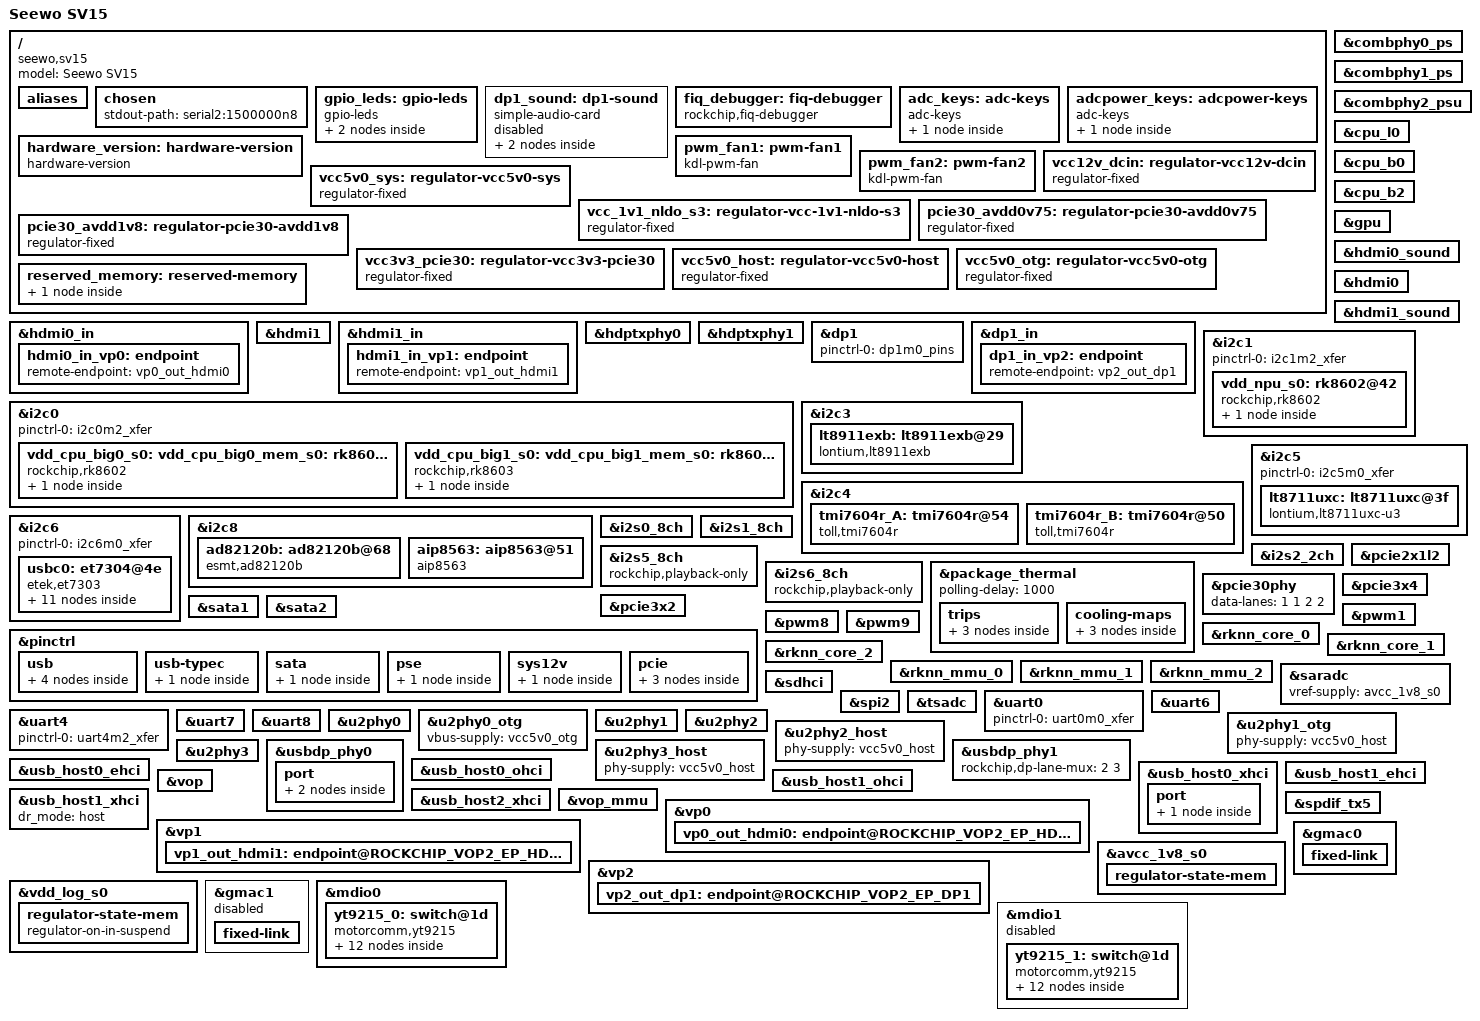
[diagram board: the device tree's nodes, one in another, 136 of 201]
// SPDX-License-Identifier: (GPL-2.0+ OR MIT)
/*
 * Copyright (c) 2026 ColtPlus
 */

/dts-v1/;

#include <dt-bindings/gpio/gpio.h>
#include <dt-bindings/leds/common.h>
#include <dt-bindings/pwm/pwm.h>
#include <dt-bindings/pinctrl/rockchip.h>
#include <dt-bindings/input/linux-event-codes.h>
#include <dt-bindings/soc/rockchip,vop2.h>
#include <dt-bindings/usb/pd.h>
#include "rk3588.dtsi"
#include "rk3588-rk806-single.dtsi"

/ {
	model = "Seewo SV15";
	compatible = "seewo,sv15", "rockchip,rk3588";

	aliases {
		mmc0 = &sdmmc;
		mmc1 = &sdhci;
		mmc2 = &sdio;
	};

	chosen {
		stdout-path = "serial2:1500000n8";
	};

	gpio_leds: gpio-leds {
		compatible = "gpio-leds";
		pinctrl-names = "default";

		user-led {
			gpios = <&gpio4 RK_PD0 GPIO_ACTIVE_HIGH>;
			linux,default-trigger = "boot";
			default-state = "on";
		};

		sys-led {
			gpios = <&gpio4 RK_PD1 GPIO_ACTIVE_HIGH>;
			linux,default-trigger = "alarm";
		};
	};

	dp1_sound: dp1-sound {
		compatible = "simple-audio-card";
		simple-audio-card,name = "rockchip,dp1";
		simple-audio-card,mclk-fs = <512>;
		status = "disabled";

		simple-audio-card, {
			sound-dai = <&spdif_tx5>;
		};

		simple-audio-card,codec {
			sound-dai = <&dp1>;
		};
	};

	fiq_debugger: fiq-debugger {
		compatible = "rockchip,fiq-debugger";
		rockchip,serial-id = <2>;
		rockchip,wake-irq = <0>;
		rockchip,irq-mode-enable = <1>;
		rockchip,baudrate = <1500000>;
		interrupts = <GIC_SPI 423 IRQ_TYPE_LEVEL_LOW>;
		pinctrl-names = "default";
		pinctrl-0 = <&uart2m0_xfer>;
		status = "okay";
	};

	adc_keys: adc-keys {
		compatible = "adc-keys";
		io-channels = <&saradc 1>;
		io-channel-names = "buttons";
		keyup-threshold-microvolt = <1800000>;
		poll-interval = <100>;

		vol-up-key {
			label = "volume up";
			linux,code = <KEY_VOLUMEUP>;
			press-threshold-microvolt = <1750>;
		};
	};

	adcpower_keys: adcpower-keys {
		compatible = "adc-keys";
		io-channels = <&saradc 3>;
		io-channel-names = "buttons";
		keyup-threshold-microvolt = <1800000>;
		poll-interval = <100>;

		adc-power-key {
			label = "power key";
			linux,code = <KEY_POWER>;
			press-threshold-microvolt = <1750>;
			wakeup-source;
		};
	};

	hardware_version: hardware-version {
		compatible = "hardware-version";
		io-channels = <&saradc 5 &saradc 7>;
		io-channel-names = "ADC5", "ADC7";
		keyup-threshold-microvolt = <1800000>;
		poll-interval = <100>;
	};


	pwm_fan1: pwm-fan1 {
		compatible = "kdl-pwm-fan";
		pwm-names = "fan1";
		pwms = <&pwm8 0 40000 0>;
		pwm-frequency = <25000>;
		rd-gpios = <&gpio3 RK_PA0 GPIO_ACTIVE_HIGH>;
		pwm-polarity-inversed;
	};

	pwm_fan2: pwm-fan2 {
		compatible = "kdl-pwm-fan";
		pwm-names = "fan2";
		pwms = <&pwm9 0 40000 0>;
		pwm-frequency = <25000>;
		rd-gpios = <&gpio3 RK_PA1 GPIO_ACTIVE_HIGH>;
		pwm-polarity-inversed;
	};

	vcc12v_dcin: regulator-vcc12v-dcin {
		compatible = "regulator-fixed";
		regulator-name = "vcc12v_dcin";
		regulator-always-on;
		regulator-boot-on;
		regulator-min-microvolt = <12000000>;
		regulator-max-microvolt = <12000000>;
	};

	vcc5v0_sys: regulator-vcc5v0-sys {
		compatible = "regulator-fixed";
		regulator-name = "vcc5v0_sys";
		regulator-always-on;
		regulator-boot-on;
		regulator-min-microvolt = <5000000>;
		regulator-max-microvolt = <5000000>;
		vin-supply = <&vcc12v_dcin>;
	};

	vcc_1v1_nldo_s3: regulator-vcc-1v1-nldo-s3 {
		compatible = "regulator-fixed";
		regulator-name = "vcc_1v1_nldo_s3";
		regulator-always-on;
		regulator-boot-on;
		regulator-min-microvolt = <1100000>;
		regulator-max-microvolt = <1100000>;
		vin-supply = <&vcc5v0_sys>;
	};

	pcie30_avdd0v75: regulator-pcie30-avdd0v75 {
		compatible = "regulator-fixed";
		regulator-name = "pcie30_avdd0v75";
		regulator-boot-on;
		regulator-always-on;
		regulator-min-microvolt = <750000>;
		regulator-max-microvolt = <750000>;
		vin-supply = <&vdd_0v75_s0>;
	};

	pcie30_avdd1v8: regulator-pcie30-avdd1v8 {
		compatible = "regulator-fixed";
		regulator-name = "pcie30_avdd1v8";
		regulator-boot-on;
		regulator-always-on;
		regulator-min-microvolt = <1800000>;
		regulator-max-microvolt = <1800000>;
		vin-supply = <&avcc_1v8_s0>;
	};

	vcc3v3_pcie30: regulator-vcc3v3-pcie30 {
		compatible = "regulator-fixed";
		enable-active-high;
		gpios = <&gpio1 RK_PB6 GPIO_ACTIVE_HIGH>;
		regulator-name = "vcc3v3_pcie30";
		regulator-min-microvolt = <3300000>;
		regulator-max-microvolt = <3300000>;
		startup-delay-us = <7500>;
		vin-supply = <&vcc12v_dcin>;
	};

	vcc5v0_host: regulator-vcc5v0-host {
		compatible = "regulator-fixed";
		regulator-name = "vcc5v0_host";
		regulator-boot-on;
		regulator-always-on;
		regulator-min-microvolt = <5000000>;
		regulator-max-microvolt = <5000000>;
		vin-supply = <&vcc5v0_sys>;
		enable-active-high;
		gpio = <&gpio4 RK_PB0 GPIO_ACTIVE_HIGH>;
		pinctrl-names = "default";
		pinctrl-0 = <&vcc5v0_host_en>;
	};

	vcc5v0_otg: regulator-vcc5v0-otg {
		compatible = "regulator-fixed";
		regulator-name = "vcc5v0_otg";
		regulator-boot-on;
		regulator-always-on;
		regulator-min-microvolt = <5000000>;
		regulator-max-microvolt = <5000000>;
		enable-active-high;
		gpio = <&gpio4 RK_PA3 GPIO_ACTIVE_HIGH>;
		vin-supply = <&vcc5v0_sys>;
		pinctrl-names = "default";
		pinctrl-0 = <&vcc5v0_otg_en>;
	};

	reserved_memory: reserved-memory {
		#address-cells = <2>;
		#size-cells = <2>;
		ranges;

		cma: linux,cma@10000000 {
			compatible = "shared-dma-pool";
			reusable;
			reg = <0x0 (256 * 0x100000) 0x0 (256 * 0x100000)>;
			linux,cma-default;
		};
	};
};

&combphy0_ps {
	status = "okay";
};

&combphy1_ps {
	status = "okay";
};

&combphy2_psu {
	status = "okay";
};

&cpu_l0 {
	cpu-supply = <&vdd_cpu_lit_s0>;
	mem-supply = <&vdd_cpu_lit_mem_s0>;
};

&cpu_b0 {
	cpu-supply = <&vdd_cpu_big0_s0>;
	mem-supply = <&vdd_cpu_big0_mem_s0>;
};

&cpu_b2 {
	cpu-supply = <&vdd_cpu_big1_s0>;
	mem-supply = <&vdd_cpu_big1_mem_s0>;
};

&gpu {
	upthreshold = <30>;
	downdifferential = <10>;
	mali-supply = <&vdd_gpu_s0>;
	mem-supply = <&vdd_gpu_mem_s0>;
	status = "okay";
};

&hdmi0_sound {
	status = "okay";
};

&hdmi0 {
	pinctrl-names = "default";
	pinctrl-0 = <&hdmim0_tx0_hpd &hdmim0_tx0_scl &hdmim0_tx0_sda>;
	frl-enable-gpios = <&gpio4 RK_PB5 GPIO_ACTIVE_LOW>;
	status = "okay";
};

&hdmi0_in {
	hdmi0_in_vp0: endpoint {
		remote-endpoint = <&vp0_out_hdmi0>;
	};
};

&hdmi1_sound {
	status = "okay";
};

&hdmi1 {
	pinctrl-names = "default";
	pinctrl-0 = <&hdmim0_tx1_hpd &hdmim1_tx1_scl &hdmim1_tx1_sda>;
	frl-enable-gpios = <&gpio4 RK_PB6 GPIO_ACTIVE_LOW>;
	status = "okay";
};

&hdmi1_in {
	hdmi1_in_vp1: endpoint {
		remote-endpoint = <&vp1_out_hdmi1>;
	};
};

&hdptxphy0 {
	status = "okay";
};

&hdptxphy1 {
	status = "okay";
};

&dp1 {
	status = "okay";
	pinctrl-0 = <&dp1m0_pins>;
	pinctrl-names = "default";
};

&dp1_in {
	dp1_in_vp2: endpoint {
		remote-endpoint = <&vp2_out_dp1>;
	};
};

&i2c0 {
	status = "okay";
	pinctrl-names = "default";
	pinctrl-0 = <&i2c0m2_xfer>;

	vdd_cpu_big0_s0: vdd_cpu_big0_mem_s0: rk8602@42 {
		compatible = "rockchip,rk8602";
		reg = <0x42>;
		vin-supply = <&vcc5v0_sys>;
		fcs,suspend-voltage-selector = <1>;
		regulator-name = "vdd_cpu_big0_s0";
		regulator-min-microvolt = <550000>;
		regulator-max-microvolt = <1050000>;
		regulator-ramp-delay = <2300>;
		regulator-boot-on;
		regulator-always-on;

		regulator-state-mem {
			regulator-off-in-suspend;
		};
	};

	vdd_cpu_big1_s0: vdd_cpu_big1_mem_s0: rk8603@43 {
		compatible = "rockchip,rk8603", "rockchip,rk8602";
		reg = <0x43>;
		vin-supply = <&vcc5v0_sys>;
		fcs,suspend-voltage-selector = <1>;
		regulator-name = "vdd_cpu_big1_s0";
		regulator-min-microvolt = <550000>;
		regulator-max-microvolt = <1050000>;
		regulator-ramp-delay = <2300>;
		regulator-boot-on;
		regulator-always-on;

		regulator-state-mem {
			regulator-off-in-suspend;
		};
	};
};

&i2c1 {
	status = "okay";
	pinctrl-names = "default";
	pinctrl-0 = <&i2c1m2_xfer>;

	vdd_npu_s0: rk8602@42 {
		compatible = "rockchip,rk8602";
		reg = <0x42>;
		vin-supply = <&vcc5v0_sys>;
		fcs,suspend-voltage-selector = <1>;
		regulator-name = "vdd_npu_s0";
		regulator-min-microvolt = <550000>;
		regulator-max-microvolt = <950000>;
		regulator-ramp-delay = <2300>;
		regulator-boot-on;
		regulator-always-on;

		regulator-state-mem {
			regulator-off-in-suspend;
		};
	};
};

&i2c3 {
	pinctrl-names = "default";
	pinctrl-0 = <&i2c3m0_xfer>;
	clock-frequency = <100000>;
	status = "okay";

	lt8911exb: lt8911exb@29 {
		compatible = "lontium,lt8911exb";
		reg = <0x29>;
		/*bl-on-gpios = <0x12c 0x0f 0x00>;
		panel-pwren-gpios = <0x12d 0x14 0x00>;
		bl-pwren-gpios = <0x12d 0x15 0x00>;
		rst-gpios = <0xf1 0x14 0x00>;*/
		bl-on-gpios = <&gpio0 RK_PB7 GPIO_ACTIVE_HIGH>;
		panel-pwren-gpios = <&gpio2 RK_PC4 GPIO_ACTIVE_HIGH>;
		bl-pwren-gpios = <&gpio2 RK_PC5 GPIO_ACTIVE_HIGH>;
		reset-gpios = <&gpio1 RK_PC4 GPIO_ACTIVE_HIGH>;
		status = "okay";
	};
};

&i2c4 {
	status = "okay";
	
	tmi7604r_A: tmi7604r@54 {
		status = "okay";
		compatible = "toll,tmi7604r";
		kdl,poe-module-name = "tmi7604r_A";
		reg = <0x54>;
		/*pse-intb-gpios = <0xf1 0x1e 0x00>;*/
		pse-intb-gpios = <&gpio1 RK_PD6 GPIO_ACTIVE_HIGH>;
		my-conf = <0x01>;
	};

	tmi7604r_B: tmi7604r@50 {
		status = "okay";
		compatible = "toll,tmi7604r";
		kdl,poe-module-name = "tmi7604r_B";
		reg = <0x50>;
		/*pse-intb-gpios = <0xf1 0x13 0x00>;*/
		pse-intb-gpios = <&gpio1 RK_PC3 GPIO_ACTIVE_HIGH>;
		my-conf = <0x02>;
	};
};

&i2c5 {
	#address-cells = <1>;
	#size-cells = <0>;
	pinctrl-names = "default";
	pinctrl-0 = <&i2c5m0_xfer>;
	status = "okay";

	/*lt6911c_A: lt6911c_A@2b {
		status = "okay";
		compatible = "lontium,lt6911c";
		reg = <0x2b>;
		clocks = <&cru CLK_MIPI_CAMARAOUT_M2>;
		clock-names = "xvclk";
		reset-gpios = <&gpio4 RK_PC1 GPIO_ACTIVE_HIGH>;
		res-change-gpios = <&gpio3 RK_PC3 GPIO_ACTIVE_HIGH>;
		plugin-det-gpios = <&gpio3 RK_PD1 GPIO_ACTIVE_HIGH>;
		rockchip,camera-module-index = <0>;
		rockchip,camera-module-facing = "back";
		rockchip,camera-module-name = "lt6911c_A";
		rockchip,camera-module-lens-name = "NC";
		cvte,hdmi-port-name = "HDMIIN1";

		port {

			endpoint {
				remote-endpoint = <&csi2_dcphy1_ports_port0_endpoint1>;
				data-lanes = <1 2 3 4>;
			};
		};
	};*/

	lt8711uxc: lt8711uxc@3f {
		compatible = "lontium,lt8711uxc-u3";
		reg = <0x3f>;
		plugin-det-gpios = <&gpio3 RK_PD5 GPIO_ACTIVE_HIGH>;
		reset-gpios = <&gpio3 RK_PB2 GPIO_ACTIVE_HIGH>;
		status = "okay";
	};
};

&i2c6 {
	pinctrl-names = "default";
	pinctrl-0 = <&i2c6m0_xfer>;
	status = "okay";

	usbc0: et7304@4e {
		compatible = "etek,et7303";
		reg = <0x4e>;
		interrupt-parent = <&gpio4>;
		interrupts = <RK_PA4 IRQ_TYPE_LEVEL_LOW>;
		pinctrl-names = "default";
		pinctrl-0 = <&usbc0_int>;
		vbus-supply = <&vcc5v0_otg>;
		status = "okay";

		ports {
			#address-cells = <1>;
			#size-cells = <0>;

			port@0 {
				reg = <0>;
				usbc0_role_sw: endpoint {
					remote-endpoint = <&dwc3_0_role_switch>;
				};
			};
		};

		usb_con: connector {
			compatible = "usb-c-connector";
			label = "USB-C";
			data-role = "dual";
			power-role = "dual";
			try-power-role = "sink";
			op-sink-microwatt = <1000000>;
			sink-pdos = <PDO_FIXED(5000, 1000, PDO_FIXED_USB_COMM)>;
			source-pdos = <PDO_FIXED(5000, 3000, PDO_FIXED_USB_COMM)>;

			altmodes {
				#address-cells = <1>;
				#size-cells = <0>;

				altmode@0 {
					reg = <0>;
					svid = <0xff01>;
					vdo = <0xffffffff>;
				};
			};

			ports {
				#address-cells = <1>;
				#size-cells = <0>;

				port@0 {
					reg = <0>;
					usbc0_orien_sw: endpoint {
						remote-endpoint = <&usbdp_phy0_orientation_switch>;
					};
				};

				port@1 {
					reg = <1>;
					dp_altmode_mux: endpoint {
						remote-endpoint = <&usbdp_phy0_dp_altmode_mux>;
					};
				};
			};
		};
	};
};

&i2c8 {
	pinctrl-names = "default";
	pinctrl-0 = <&i2c8m4_xfer>;
	status = "okay";
	clock-frequency = <100000>;

	ad82120b: ad82120b@68 {
		compatible = "esmt,ad82120b";
		reg = <0x68>;
		#sound-dai-cells = <0x00>;
		mute-gpios = <&gpio3 RK_PB1 GPIO_ACTIVE_HIGH>;
		no_mclk;
		status = "okay";
	};

	aip8563: aip8563@51 {
		compatible = "aip8563";
		reg = <0x51>;
		interrupt-parent = <&gpio1>;
		interrupts = <RK_PB5 IRQ_TYPE_LEVEL_LOW>;
		status = "okay";
	};
};

&i2s0_8ch {
	status = "okay";
};

&i2s1_8ch {
	pinctrl-names = "default";
	assigned-clocks = <&cru CLK_I2S1_8CH_RX>;
	assigned-clock-parents = <&cru CLK_I2S1_8CH_TX_SRC>;
	status = "okay";
};

&i2s2_2ch {
	pinctrl-names = "default";
	pinctrl-0 = <&i2s2m1_lrck
		     &i2s2m1_sclk
		     &i2s2m1_sdo>;
	status = "okay";
};

&i2s5_8ch {
	rockchip,playback-only;
	status = "okay";
};

&i2s6_8ch {
	rockchip,playback-only;
	status = "okay";
};

&package_thermal {
	polling-delay = <1000>;

	trips {
		package_fan0: package-fan0 {
			temperature = <50000>;
			hysteresis = <2000>;
			type = "active";
		};

		package_fan1: package-fan1 {
			temperature = <60000>;
			hysteresis = <2000>;
			type = "active";
		};

		package_fan2: package-fan2 {
			temperature = <70000>;
			hysteresis = <2000>;
			type = "active";
		};
	};

	cooling-maps {
		map0 {
			trip = <&package_fan0>;
			cooling-device = <&pwm_fan1 THERMAL_NO_LIMIT 2>;
		};

		map1 {
			trip = <&package_fan1>;
			cooling-device = <&pwm_fan1 3 5>;
		};

		map2 {
			trip = <&package_fan2>;
			cooling-device = <&pwm_fan1 6 THERMAL_NO_LIMIT>;
		};
	};
};

&pcie2x1l2 {
	pinctrl-names = "default";
	pinctrl-0 = <&pcie2_2_rst>;
	reset-gpios = <&gpio1 RK_PB4 GPIO_ACTIVE_HIGH>;
	status = "okay";
};

&pcie30phy {
	data-lanes = <1 1 2 2>;
	status = "okay";
};

&pcie3x4 {
	num-lanes = <2>;
	max-link-speed = <3>;
	pinctrl-names = "default";
	pinctrl-0 = <&pcie3x4_rst>;
	reset-gpios = <&gpio1 RK_PA7 GPIO_ACTIVE_HIGH>;
	vpcie3v3-supply = <&vcc3v3_pcie30>;
	status = "okay";
};

&pcie3x2 {
	num-lanes = <2>;
	max-link-speed = <3>;
	pinctrl-names = "default";
	pinctrl-0 = <&pcie3x2_rst>;
	reset-gpios = <&gpio1 RK_PB7 GPIO_ACTIVE_HIGH>;
	vpcie3v3-supply = <&vcc3v3_pcie30>;
	status = "okay";
};

&sata1 {
	status = "okay";
};

&sata2 {
	status = "okay";
};

&pinctrl {
	usb {
		vcc5v0_host_en: vcc5v0-host-en {
			rockchip,pins = <4 RK_PB0 RK_FUNC_GPIO &pcfg_pull_none>;
		};

		vcc5v0_otg_en: vcc5v0-otg-en {
			rockchip,pins = <4 RK_PA3 RK_FUNC_GPIO &pcfg_pull_none>;
		};

		usb20_pwren: usb20-pwren {
			rockchip,pins = <1 RK_PC2 RK_FUNC_GPIO &pcfg_output_high>;
		};

		usb30_pwren: usb30-pwren {
			rockchip,pins = <1 RK_PC6 RK_FUNC_GPIO &pcfg_output_high>;
		};
	};

	usb-typec {
		usbc0_int: usbc0-int {
			rockchip,pins = <4 RK_PA4 RK_FUNC_GPIO &pcfg_pull_up>;
		};
	};

	sata {
		sata_pwren: sata-pwren {
			rockchip,pins = <1 RK_PD4 RK_FUNC_GPIO &pcfg_pull_none>;
		};
	};

	pse {
		pse_pwren: pse-pwren {
			rockchip,pins = <4 RK_PA0 RK_FUNC_GPIO &pcfg_pull_none>;
		};
	};

	sys12v {
		sys12v_pwren: sys12v-pwren {
			rockchip,pins = <1 RK_PC7 RK_FUNC_GPIO &pcfg_pull_none>;
		};
	};

	pcie {
		pcie2_2_rst: pcie2-2-rst {
			rockchip,pins = <1 RK_PB4 RK_FUNC_GPIO &pcfg_pull_none>;
		};

		pcie3x2_rst: pcie3x2-rst {
			rockchip,pins = <1 RK_PB7 RK_FUNC_GPIO &pcfg_pull_none>;
		};

		pcie3x4_rst: pcie3x4-rst {
			rockchip,pins = <1 RK_PA7 RK_FUNC_GPIO &pcfg_pull_none>;
		};
	};
};

&pwm1 {
	status = "okay";
};

&pwm8 {
	status = "okay";
};

&pwm9 {
	status = "okay";
};

&rknn_core_0 {
	npu-supply = <&vdd_npu_s0>;
	sram-supply = <&vdd_npu_s0>;
	status = "okay";
};

&rknn_core_1 {
	npu-supply = <&vdd_npu_s0>;
	sram-supply = <&vdd_npu_s0>;
	status = "okay";
};

&rknn_core_2 {
	npu-supply = <&vdd_npu_s0>;
	sram-supply = <&vdd_npu_s0>;
	status = "okay";
};

&rknn_mmu_0 {
	status = "okay";
};

&rknn_mmu_1 {
	status = "okay";
};

&rknn_mmu_2 {
	status = "okay";
};

&saradc {
	vref-supply = <&avcc_1v8_s0>;
	status = "okay";
};

&sdhci {
	bus-width = <8>;
	no-sdio;
	no-sd;
	non-removable;
	mmc-hs400-1_8v;
	mmc-hs400-enhanced-strobe;
	status = "okay";
};

&spi2 {
	status = "okay";
};

&tsadc {
	status = "okay";
};

&uart0 {
	pinctrl-0 = <&uart0m0_xfer>;
	status = "okay";
};

&uart4 {
	pinctrl-0 = <&uart4m2_xfer>;
	status = "okay";
};

&uart6 {
	status = "okay";
};

&uart7 {
	status = "okay";
};

&uart8 {
	status = "okay";
};

&u2phy0 {
	status = "okay";
};

&u2phy0_otg {
	vbus-supply = <&vcc5v0_otg>;
	status = "okay";
};

&u2phy1 {
	status = "okay";
};

&u2phy1_otg {
	phy-supply = <&vcc5v0_host>;
	status = "okay";
};

&u2phy2 {
	status = "okay";
};

&u2phy2_host {
	phy-supply = <&vcc5v0_host>;
	status = "okay";
};

&u2phy3 {
	status = "okay";
};

&u2phy3_host {
	phy-supply = <&vcc5v0_host>;
	status = "okay";
};

&usbdp_phy0 {
	orientation-switch;
	svid = <0xff01>;
	sbu1-dc-gpios = <&gpio0 RK_PC6 GPIO_ACTIVE_HIGH>;
	sbu2-dc-gpios = <&gpio0 RK_PD3 GPIO_ACTIVE_HIGH>;
	status = "okay";

	port {
		#address-cells = <1>;
		#size-cells = <0>;

		usbdp_phy0_orientation_switch: endpoint@0 {
			reg = <0>;
			remote-endpoint = <&usbc0_orien_sw>;
		};

		usbdp_phy0_dp_altmode_mux: endpoint@1 {
			reg = <1>;
			remote-endpoint = <&dp_altmode_mux>;
		};
	};
};

&usbdp_phy1 {
	rockchip,dp-lane-mux = <2 3>;
	status = "okay";
};

&usb_host0_ehci {
	status = "okay";
};

&usb_host0_ohci {
	status = "okay";
};

&usb_host0_xhci {
	dr_mode = "peripheral";
	usb-role-switch;
	status = "okay";

	port {
		dwc3_0_role_switch: endpoint {
			remote-endpoint = <&usbc0_role_sw>;
		};
	};
};

&usb_host1_ehci {
	status = "okay";
};

&usb_host1_ohci {
	status = "okay";
};

&usb_host1_xhci {
	dr_mode = "host";
	status = "okay";
};

&usb_host2_xhci {
	status = "okay";
};

&vop {
	status = "okay";
};

&vop_mmu {
	status = "okay";
};

&vp0 {
	vp0_out_hdmi0: endpoint@ROCKCHIP_VOP2_EP_HDMI0 {
		reg = <ROCKCHIP_VOP2_EP_HDMI0>;
		remote-endpoint = <&hdmi0_in_vp0>;
	};
};

&vp1 {
	vp1_out_hdmi1: endpoint@ROCKCHIP_VOP2_EP_HDMI1 {
		reg = <ROCKCHIP_VOP2_EP_HDMI1>;
		remote-endpoint = <&hdmi1_in_vp1>;
	};
};

&vp2 {
	vp2_out_dp1: endpoint@ROCKCHIP_VOP2_EP_DP1 {
		reg = <ROCKCHIP_VOP2_EP_DP1>;
		remote-endpoint = <&dp1_in_vp2>;
	};
};

/*&wdt {
	status = "disabled";
};*/

&spdif_tx5 {
	status = "okay";
};

&avcc_1v8_s0 {
	regulator-state-mem {
		regulator-on-in-suspend;
		regulator-suspend-microvolt = <1800000>;
	};
};

&vdd_log_s0 {
	regulator-state-mem {
		regulator-on-in-suspend;
	};
};

&gmac0 {
	status = "okay";
	phy-mode = "rgmii";
	clock_in_out = "output";
	pinctrl-names = "default";
	pinctrl-0 = <&gmac0_miim &gmac0_tx_bus2 &gmac0_rx_bus2 &gmac0_rgmii_clk &gmac0_rgmii_bus>;
	tx_delay = <58>;
	rx_delay = <0>;
	fixed-link {
		speed = <1000>;
		full-duplex;
	};
};

&gmac1 {
	status = "disabled";
	phy-mode = "rgmii";
	clock_in_out = "output";
	/*snps,reset-gpio = <0xe6 0x13 0x00>;*/
	snps,reset-gpio = <&gpio4 RK_PC3 GPIO_ACTIVE_HIGH>;
	snps,reset-active-high;
	snps,reset-delays-us = <0 250000 500000>;
	pinctrl-names = "default";
	pinctrl-0 = <&gmac1_miim &gmac1_tx_bus2 &gmac1_rx_bus2 &gmac1_rgmii_clk &gmac1_rgmii_bus>;
	tx_delay = <66>;
	rx_delay = <79>;
	fixed-link {
		speed = <1000>;
		full-duplex;
	};
};

&mdio0 {
	status = "okay";

	yt9215_0: switch@1d {
		compatible = "motorcomm,yt9215";
		reg = <0x1d>;
		dsa,member = <0 2>;

		mdio {
			#address-cells = <1>;
			#size-cells = <0>;

			sw1phy1: phy@1 { reg = <1>; };
			sw1phy2: phy@2 { reg = <2>; };
			sw1phy3: phy@3 { reg = <3>; };
			sw1phy4: phy@4 { reg = <4>; };
		};

		ethernet-ports {
			#address-cells = <1>;
			#size-cells = <0>;

			ethernet-port@1 {
				reg = <0x01>;
				label = "lan1";
				phy-mode = "internal";
				phy-handle = <&sw1phy1>;
			};

			ethernet-port@2 {
				reg = <0x02>;
				label = "lan2";
				phy-mode = "internal";
				phy-handle = <&sw1phy2>;
			};

			ethernet-port@3 {
				reg = <0x03>;
				label = "lan3";
				phy-mode = "internal";
				phy-handle = <&sw1phy3>;
			};

			ethernet-port@4 {
				reg = <0x04>;
				label = "lan4";
				phy-mode = "internal";
				phy-handle = <&sw1phy4>;
			};

			ethernet-port@9 {
				reg = <0x09>;
				ethernet = <&gmac0>;
				phy-mode = "rgmii";

				fixed-link {
					speed = <1000>;
					full-duplex;
					pause;
				};
			};
		};
	};
};

&mdio1 {
	status = "disabled";

	yt9215_1: switch@1d {
		compatible = "motorcomm,yt9215";
		reg = <0x1d>;
		dsa,member = <1 2>;

		mdio {
			#address-cells = <1>;
			#size-cells = <0>;

			sw0phy1: phy@1 { reg = <1>; };
			sw0phy2: phy@2 { reg = <2>; };
			sw0phy3: phy@3 { reg = <3>; };
			sw0phy4: phy@4 { reg = <4>; };
		};

		ethernet-ports {
			#address-cells = <0x01>;
			#size-cells = <0x00>;

			ethernet-port@1 {
				reg = <0x01>;
				label = "lan5";
				phy-mode = "internal";
				phy-handle = <&sw0phy1>;
			};

			ethernet-port@2 {
				reg = <0x02>;
				label = "lan6";
				phy-mode = "internal";
				phy-handle = <&sw0phy2>;
			};

			ethernet-port@3 {
				reg = <0x03>;
				label = "lan7";
				phy-mode = "internal";
				phy-handle = <&sw0phy3>;
			};

			ethernet-port@4 {
				reg = <0x04>;
				label = "lan8";
				phy-mode = "internal";
				phy-handle = <&sw0phy4>;
			};

			ethernet-port@9 {
				reg = <0x09>;
				ethernet = <&gmac1>;
				phy-mode = "rgmii";

				fixed-link {
					speed = <1000>;
					full-duplex;
					pause;
				};
			};
		};
	};
};

#include "rk3588-seewo-vngpu.dtsi"
